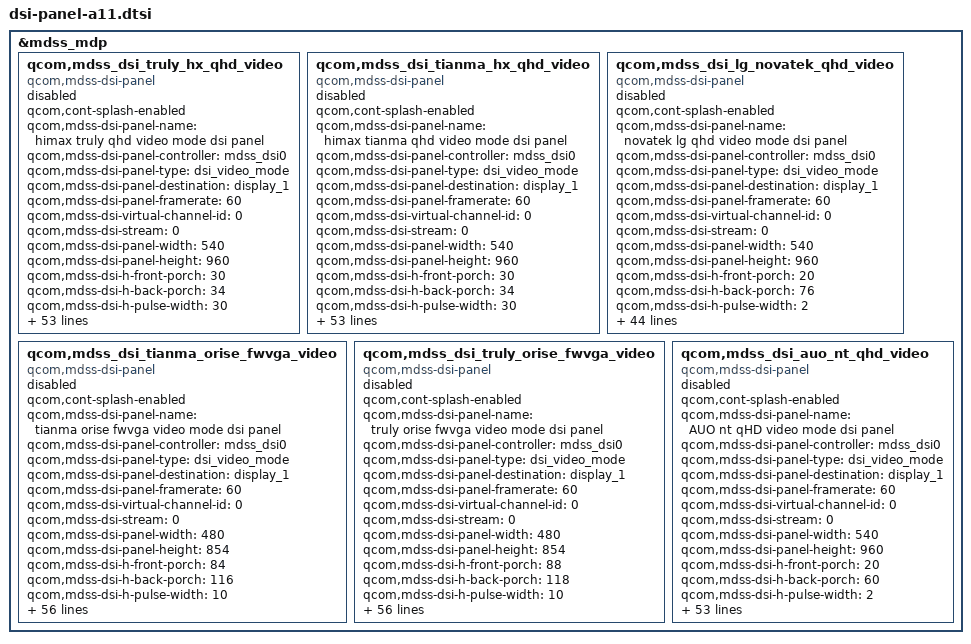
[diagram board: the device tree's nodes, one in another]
&mdss_mdp {
	qcom,mdss_dsi_truly_hx_qhd_video {
		compatible = "qcom,mdss-dsi-panel";
		status = "disabled";
		qcom,cont-splash-enabled;
		qcom,mdss-dsi-panel-name = "himax truly qhd video mode dsi panel";
		qcom,mdss-dsi-panel-controller = <&mdss_dsi0>;
		qcom,mdss-dsi-panel-type = "dsi_video_mode";

		qcom,mdss-dsi-panel-destination = "display_1";
		qcom,mdss-dsi-panel-framerate = <60>;
		qcom,mdss-dsi-virtual-channel-id = <0>;
		qcom,mdss-dsi-stream = <0>;
		qcom,mdss-dsi-panel-width = <540>;
		qcom,mdss-dsi-panel-height = <960>;
		qcom,mdss-dsi-h-front-porch = <30>;
		qcom,mdss-dsi-h-back-porch = <34>;
		qcom,mdss-dsi-h-pulse-width = <30>;
		qcom,mdss-dsi-h-sync-skew = <0>;
		qcom,mdss-dsi-v-back-porch = <13>;
		qcom,mdss-dsi-v-front-porch = <8>;
		qcom,mdss-dsi-v-pulse-width = <5>;
		qcom,mdss-dsi-h-left-border = <0>;
		qcom,mdss-dsi-h-right-border = <0>;
		qcom,mdss-dsi-v-top-border = <0>;
		qcom,mdss-dsi-v-bottom-border = <0>;
		qcom,mdss-dsi-bpp = <24>;
		qcom,mdss-dsi-color-order = <0>;
		qcom,mdss-dsi-underflow-color = <0xff>;
		qcom,mdss-dsi-border-color = <0>;
		/*
			. init command patched
			. 0xE0, 0xC1 command patched
		*/
		qcom,mdss-dsi-on-command = [
			39 01 00 00 01 00 04 B9 FF 83 89
			39 01 00 00 01 00 08 BA 41 93 00 16 A4 00 18
			39 01 00 00 01 00 02 C6 08
			39 01 00 00 01 00 02 CC 02
			39 01 00 00 01 00 03 C0 43 15

			39 01 00 00 01 00 14 B1 00 00 04 E3 9E 10 11 6F EF 28 30 23 23 42 00 58 F2 20 00
			39 01 00 00 01 00 04 DE 05 58 10
			39 01 00 00 0A 00 08 B2 00 00 78 08 03 00 80

			39 01 00 00 0A 00 18 B4 80 08 00 32 10 00 00 00 00 00 00 00 37 0A 40 04 37 0A 40 14 FF FF 0A

			39 01 00 00 0A 00 31 D5 00 00 4C 00 01 00 00 00 60 00 99 88 99 88 88 32 88 10 88 76 88 54 10 32 88 88 88 88 88 88 99 88 99 88 45 88 67 88 01 88 23 23 01 88 88 88 88 88

			39 01 00 00 05 00 23 E0 00 05 09 2A 2E 3F 15 37 05 0B 10 12 14 12 13 11 19 00 04 08 2A 2F 3F 16 38 06 0C 0E 11 13 12 13 10 17
			39 01 00 00 01 00 80 C1 01 00 0B 14 1A 24 2B 33 3B 44 4B 54 5C 64 6D 75 7D 85 8D 95 9E A7 B0 B8 C0 C8 CD D5 DD E4 EB F4 F8 FF 12 3B 72 92 5D 00 73 B3 C0 00 08 11 18 20 27 2F 37 3E 46 4D 55 5C 64 6C 74 7B 82 8A 92 9A A2 AB B4 BB C4 CB D1 DA E3 EB F5 FE 20 68 81 F4 B8 64 E3 51 C0 00 06 0D 15 1D 25 2D 35 3C 44 4B 53 5A 62 6A 71 79 80 87 8E 96 9D A5 AD B4 BC C4 CA D0 D8 E1 E8 F0 00 AC D5 F2 1B 74 C6 A4 00

			39 01 00 00 01 00 02 35 01
			39 01 00 00 01 00 0A C9 0F 00 01 10 00 00 00 01 3A
			/* CABC Command Start */
			39 01 00 00 01 00 02 55 02
			39 01 00 00 01 00 02 5E 11
			39 01 00 00 01 00 0A CA 2D 27 26 25 24 22 21 20 20
			39 01 00 00 01 00 23 CE 00 10 10 10 10 16 16 16 16 16 16 16 16 16 00 00 00 00 00 00 00 00 00 00 00 00 00 00 00 00 00 00 00 00
			/* CABC Command End */
			39 01 00 00 01 00 02 53 2C
			39 01 00 00 01 00 02 E6 00
			39 01 00 00 01 00 02 E3 01
			05 01 00 00 C8 00 02 11 00
			];
		qcom,mdss-dsi-off-command = [05 01 00 00 01 00 02 28 00
					05 01 00 00 78 00 02 10 00];
		qcom,mdss-dsi-on-command-state = "dsi_lp_mode";
		qcom,mdss-dsi-off-command-state = "dsi_hs_mode";
		qcom,mdss-dsi-h-sync-pulse = <1>;
		qcom,mdss-dsi-traffic-mode = <1>;
		qcom,mdss-dsi-bllp-eof-power-mode;
		qcom,mdss-dsi-lane-map = <0>;
		qcom,mdss-dsi-bllp-power-mode;
		qcom,mdss-dsi-lane-0-state;
		qcom,mdss-dsi-lane-1-state;
		qcom,mdss-dsi-panel-timings =  [87 20 12 00 40 44 16 22 17 03 04 00];
		qcom,mdss-dsi-t-clk-post = <0x1f>;
		qcom,mdss-dsi-t-clk-pre = <0x39>;
		qcom,mdss-dsi-bl-min-level = <1>;
		qcom,mdss-dsi-bl-max-level = <255>;
		qcom,mdss-dsi-dma-trigger = <0x04>;
		qcom,mdss-dsi-mdp-trigger = <0x0>;
		qcom,mdss-dsi-bl-pmic-control-type = "bl_ctrl_dcs";

		qcom,display-on-cmds = [05 01 00 00 64 00 02 29 00];
		qcom,mdss-dsi-default-command-state = "dsi_hs_mode";
		qcom,mdss-pan-physical-width-dimension = <58>;
		qcom,mdss-pan-physical-height-dimension = <103>;
		qcom,mdss-shrink-pwm = <16 113 255>;
		qcom,mdss-dsi-lp11-init;
		htc,mdss-camera-blk = <213>;
		htc,panel-id=<0>;
		htc,cabc-off-cmds = [
			39 01 00 00 01 00 02 55 00
			];
		htc,cabc-ui-cmds = [
			39 01 00 00 05 00 02 55 02
			39 01 00 00 01 00 02 5E 11
			39 01 00 00 01 00 0A CA 2D 27 26 25 24 22 21 20 20
			39 01 00 00 01 00 23 CE 00 10 10 10 10 16 16 16 16 16 16 16 16 16 00 00 00 00 00 00 00 00 00 00 00 00 00 00 00 00 00 00 00 00
			];
		htc,cabc-video-cmds = [
			39 01 00 00 05 00 02 55 03
			39 01 00 00 01 00 02 5E 11
			39 01 00 00 01 00 0A CA 40 30 2F 2E 2D 26 22 20 20
			39 01 00 00 01 00 23 CE 00 18 1A 1A 20 20 20 20 28 28 28 28 28 28 28 28 30 30 30 30 30 30 30 30 30 30 30 30 30 30 30 30 30 00
			];
		htc,dimming-on-cmds = [39 01 00 00 00 00 02 53 2C];
	};
	qcom,mdss_dsi_tianma_hx_qhd_video {
		compatible = "qcom,mdss-dsi-panel";
		status = "disabled";
		qcom,cont-splash-enabled;
		qcom,mdss-dsi-panel-name = "himax tianma qhd video mode dsi panel";
		qcom,mdss-dsi-panel-controller = <&mdss_dsi0>;
		qcom,mdss-dsi-panel-type = "dsi_video_mode";

		qcom,mdss-dsi-panel-destination = "display_1";
		qcom,mdss-dsi-panel-framerate = <60>;
		qcom,mdss-dsi-virtual-channel-id = <0>;
		qcom,mdss-dsi-stream = <0>;
		qcom,mdss-dsi-panel-width = <540>;
		qcom,mdss-dsi-panel-height = <960>;
		qcom,mdss-dsi-h-front-porch = <30>;
		qcom,mdss-dsi-h-back-porch = <34>;
		qcom,mdss-dsi-h-pulse-width = <30>;
		qcom,mdss-dsi-h-sync-skew = <0>;
		qcom,mdss-dsi-v-back-porch = <13>;
		qcom,mdss-dsi-v-front-porch = <8>;
		qcom,mdss-dsi-v-pulse-width = <5>;
		qcom,mdss-dsi-h-left-border = <0>;
		qcom,mdss-dsi-h-right-border = <0>;
		qcom,mdss-dsi-v-top-border = <0>;
		qcom,mdss-dsi-v-bottom-border = <0>;
		qcom,mdss-dsi-bpp = <24>;
		qcom,mdss-dsi-color-order = <0>;
		qcom,mdss-dsi-underflow-color = <0xff>;
		qcom,mdss-dsi-border-color = <0>;
		/*
			. init command patched
		*/
		qcom,mdss-dsi-on-command = [
			/* exit sleep */
			05 01 00 00 78 00 02 11 00

			39 01 00 00 01 00 04 B9 FF 83 89
			39 01 00 00 01 00 08 BA 41 93 00 16 A4 00 18
			39 01 00 00 01 00 02 C6 08
			39 01 00 00 01 00 02 CC 02
			39 01 00 00 01 00 14 B1 00 00 07 DE 41 10 11 93 EE 26 2E 3F 3F 42 01 32 F4 20 80
			39 01 00 00 01 00 04 DE 05 58 10
			39 01 00 00 0A 00 08 B2 00 00 78 0E 03 3F 80

			39 01 00 00 0A 00 18 B4 80 08 00 32 10 07 32 10 03 32 10 07 27 01 5A 0B 37 05 4C 14 FF 58 0A

			39 01 00 00 0A 00 31 D5 00 00 00 00 01 00 00 01 60 00 99 88 88 88 88 23 88 01 88 67 88 45 01 23 23 45 88 88 88 88 99 88 88 88 54 88 76 88 10 88 32 32 10 88 88 88 88 88

			39 01 00 00 0A 00 23 E0 00 21 24 3A 3F 3F 31 4E 07 0C 0F 12 14 11 13 10 17 00 21 23 38 3F 3F 31 4D 08 0D 0E 12 14 11 13 10 19

			39 01 00 00 05 00 80 C1 01 00 06 13 18 20 2A 32 39 42 49 51 59 5F 68 71 7C 83 8B 94 9C A4 AE B6 BE C6 CA D3 DB E3 EB F3 FD FF 03 AA 62 C9 B5 C5 BA 0C C0 00 08 12 18 1F 29 31 38 40 47 4E 55 5C 62 6A 73 7B 83 8A 91 99 A1 A8 B0 B8 BF C9 CE D5 E0 E8 F0 FA 00 1A 12 3D C6 89 78 00 C0 00 08 0E 15 1D 28 31 38 40 47 4E 56 5C 63 6C 75 7D 84 8C 93 9C A3 AB B3 BB C3 CB D1 D8 E2 E9 F1 F8 03 A6 68 F4 77 3B 99 80 00
			39 01 00 00 01 00 02 35 01
			39 01 00 00 01 00 0A C9 0F 00 01 10 00 00 00 01 3A

			/* CABC Command Start */
			39 01 00 00 05 00 02 55 02
			39 01 00 00 01 00 02 5E 11
			39 01 00 00 01 00 0A CA 2D 27 26 25 24 22 21 21 20
			39 01 00 00 01 00 23 CE 00 00 00 00 10 10 16 16 16 16 16 16 16 16 00 00 00 00 00 00 00 00 00 00 00 00 00 00 00 00 00 00 00 00
			/* CABC Command End */

			/* CE Command Start */
			39 01 00 00 01 00 02 E6 00
			39 01 00 00 01 00 02 E3 01
			/* CE Command End */

			39 01 00 00 01 00 02 53 2C
			];
		qcom,mdss-dsi-off-command = [05 01 00 00 01 00 02 28 00
					05 01 00 00 78 00 02 10 00];
		qcom,mdss-dsi-on-command-state = "dsi_lp_mode";
		qcom,mdss-dsi-off-command-state = "dsi_hs_mode";
		qcom,mdss-dsi-h-sync-pulse = <1>;
		qcom,mdss-dsi-traffic-mode = <1>;
		qcom,mdss-dsi-bllp-eof-power-mode;
		qcom,mdss-dsi-lane-map = <0>;
		qcom,mdss-dsi-bllp-power-mode;
		qcom,mdss-dsi-lane-0-state;
		qcom,mdss-dsi-lane-1-state;
		qcom,mdss-dsi-panel-timings =  [87 20 12 00 40 44 16 22 17 03 04 00];
		qcom,mdss-dsi-t-clk-post = <0x1f>;
		qcom,mdss-dsi-t-clk-pre = <0x39>;
		qcom,mdss-dsi-bl-min-level = <1>;
		qcom,mdss-dsi-bl-max-level = <255>;
		qcom,mdss-dsi-dma-trigger = <0x04>;
		qcom,mdss-dsi-mdp-trigger = <0x0>;
		qcom,mdss-dsi-bl-pmic-control-type = "bl_ctrl_dcs";

		qcom,display-on-cmds = [05 01 00 00 0a 00 02 29 00];
		qcom,mdss-dsi-default-command-state = "dsi_hs_mode";
		qcom,mdss-pan-physical-width-dimension = <58>;
		qcom,mdss-pan-physical-height-dimension = <103>;
		qcom,mdss-shrink-pwm = <16 113 255>;
		qcom,mdss-dsi-lp11-init;
		htc,mdss-camera-blk = <213>;
		htc,cabc-off-cmds = [
			39 01 00 00 01 00 02 55 00
			];
		htc,cabc-ui-cmds = [
			39 01 00 00 05 00 02 55 02
			39 01 00 00 01 00 02 5E 11
			39 01 00 00 01 00 0A CA 2D 27 26 25 24 22 21 21 20
			39 01 00 00 01 00 23 CE 00 00 00 00 10 10 16 16 16 16 16 16 16 16 00 00 00 00 00 00 00 00 00 00 00 00 00 00 00 00 00 00 00 00
			];
		htc,cabc-video-cmds = [
			39 01 00 00 05 00 02 55 03
			39 01 00 00 01 00 02 5E 11
			39 01 00 00 01 00 0A CA 40 30 2F 2E 2D 26 23 21 20
			39 01 00 00 01 00 23 CE 00 00 00 10 10 10 10 20 20 20 20 20 20 20 30 30 30 30 30 30 30 30 30 30 30 30 30 30 30 30 30 30 30 00
			];
		htc,dimming-on-cmds = [39 01 00 00 00 00 02 53 2C];
		htc,panel-id=<0>;
	};

	qcom,mdss_dsi_lg_novatek_qhd_video{
		compatible = "qcom,mdss-dsi-panel";
		status = "disabled";
		qcom,cont-splash-enabled;
		qcom,mdss-dsi-panel-name = "novatek lg qhd video mode dsi panel";
		qcom,mdss-dsi-panel-controller = <&mdss_dsi0>;
		qcom,mdss-dsi-panel-type = "dsi_video_mode";

		qcom,mdss-dsi-panel-destination = "display_1";
		qcom,mdss-dsi-panel-framerate = <60>;
		qcom,mdss-dsi-virtual-channel-id = <0>;
		qcom,mdss-dsi-stream = <0>;
		qcom,mdss-dsi-panel-width = <540>;
		qcom,mdss-dsi-panel-height = <960>;
		qcom,mdss-dsi-h-front-porch = <20>;
		qcom,mdss-dsi-h-back-porch = <76>;
		qcom,mdss-dsi-h-pulse-width = <2>;
		qcom,mdss-dsi-h-sync-skew = <0>;
		qcom,mdss-dsi-v-back-porch = <20>;
		qcom,mdss-dsi-v-front-porch = <20>;
		qcom,mdss-dsi-v-pulse-width = <2>;
		qcom,mdss-dsi-h-left-border = <0>;
		qcom,mdss-dsi-h-right-border = <0>;
		qcom,mdss-dsi-v-top-border = <0>;
		qcom,mdss-dsi-v-bottom-border = <0>;
		qcom,mdss-dsi-bpp = <24>;
		qcom,mdss-dsi-color-order = <0>;
		qcom,mdss-dsi-underflow-color = <0xff>;
		qcom,mdss-dsi-border-color = <0>;
		qcom,mdss-dsi-on-command = [
			39 01 00 00 01 00 06 F0 55 AA 52 08 01
			15 01 00 00 01 00 02 B6 34
			15 01 00 00 01 00 02 B7 44
			15 01 00 00 01 00 02 B8 13
			15 01 00 00 01 00 02 B9 23
			39 01 00 00 01 00 04 BC 00 B8 00
			39 01 00 00 01 00 04 BD 00 B4 00
			15 01 00 00 01 00 02 BE 6A
			39 01 00 00 01 00 03 C0 04 00
			15 01 00 00 01 00 02 CF 04
			39 01 00 00 01 00 11 D1 00 75 00 B4 00 D9 00 F8 01 06 01 1F 01 31 01 52
			39 01 00 00 01 00 11 D2 01 76 01 AC 01 D1 02 0C 02 3D 02 41 02 6C 02 9E
			39 01 00 00 01 00 11 D3 02 BA 02 EC 03 12 03 34 03 4C 03 66 03 74 03 86
			39 01 00 00 01 00 05 D4 03 9B 03 C7
			15 01 00 00 78 00 02 11 00
			39 01 00 00 01 00 06 F0 55 AA 52 08 00
			39 01 00 00 01 00 04 B1 68 00 01
			15 01 00 00 01 00 02 B4 78
			39 01 00 00 01 00 05 B8 01 02 02 02
			39 01 00 00 01 00 04 BC 00 00 00
			39 01 00 00 01 00 07 C9 63 06 0D 1A 17 00
			15 01 00 00 01 00 02 53 2C
			15 01 00 00 01 00 02 35 00
			39 01 00 00 01 00 03 E0 00 02
			39 01 00 00 01 00 05 FF AA 55 25 01
			15 01 00 00 01 00 02 6F 0A
			15 01 00 00 01 00 02 FA 03
			15 01 00 00 01 00 02 13 00
			15 01 00 00 01 00 02 51 FF];
		qcom,mdss-dsi-off-command = [05 01 00 00 01 00 02 28 00
					05 01 00 00 78 00 02 10 00];
		qcom,mdss-dsi-on-command-state = "dsi_lp_mode";
		qcom,mdss-dsi-off-command-state = "dsi_hs_mode";
		qcom,mdss-dsi-h-sync-pulse = <1>;
		qcom,mdss-dsi-traffic-mode = <1>;
		qcom,mdss-dsi-bllp-eof-power-mode;
		qcom,mdss-dsi-lane-map = <0>;
		qcom,mdss-dsi-bllp-power-mode;
		qcom,mdss-dsi-lane-0-state;
		qcom,mdss-dsi-lane-1-state;
		qcom,mdss-dsi-panel-timings =  [37 27 20 01 3c 39 21 29 32 03 04 00]; //?
		qcom,mdss-dsi-t-clk-post = <0x1f>;
		qcom,mdss-dsi-t-clk-pre = <0x39>;
		qcom,mdss-dsi-bl-min-level = <1>;
		qcom,mdss-dsi-bl-max-level = <255>;
		qcom,mdss-dsi-dma-trigger = <0x04>;
		qcom,mdss-dsi-mdp-trigger = <0x0>;
		qcom,mdss-dsi-bl-pmic-control-type = "bl_ctrl_dcs";

		qcom,display-on-cmds = [05 01 00 00 01 00 02 29 00];
		qcom,mdss-dsi-default-command-state = "dsi_hs_mode";
		qcom,mdss-pan-physical-width-dimension = <61>;
		qcom,mdss-pan-physical-height-dimension = <106>;
		qcom,mdss-shrink-pwm = <16 113 255>;
		htc,mdss-camera-blk = <213>;
		htc,panel-id=<0>;
	};
	qcom,mdss_dsi_tianma_orise_fwvga_video{
		compatible = "qcom,mdss-dsi-panel";
		status = "disabled";
		qcom,cont-splash-enabled;
		qcom,mdss-dsi-panel-name = "tianma orise fwvga video mode dsi panel";
		qcom,mdss-dsi-panel-controller = <&mdss_dsi0>;
		qcom,mdss-dsi-panel-type = "dsi_video_mode";

		qcom,mdss-dsi-panel-destination = "display_1";
		qcom,mdss-dsi-panel-framerate = <60>;
		qcom,mdss-dsi-virtual-channel-id = <0>;
		qcom,mdss-dsi-stream = <0>;
		qcom,mdss-dsi-panel-width = <480>;
		qcom,mdss-dsi-panel-height = <854>;
		qcom,mdss-dsi-h-front-porch = <84>;
		qcom,mdss-dsi-h-back-porch = <116>;
		qcom,mdss-dsi-h-pulse-width = <10>;
		qcom,mdss-dsi-h-sync-skew = <0>;
		qcom,mdss-dsi-v-back-porch = <18>;
		qcom,mdss-dsi-v-front-porch = <18>;
		qcom,mdss-dsi-v-pulse-width = <12>;
		qcom,mdss-dsi-h-left-border = <0>;
		qcom,mdss-dsi-h-right-border = <0>;
		qcom,mdss-dsi-v-top-border = <0>;
		qcom,mdss-dsi-v-bottom-border = <0>;
		qcom,mdss-dsi-bpp = <24>;
		qcom,mdss-dsi-color-order = <0>;
		qcom,mdss-dsi-underflow-color = <0xff>;
		qcom,mdss-dsi-border-color = <0>;
		/*
			. init command patched : add CABC cmds
		*/
		qcom,mdss-dsi-on-command = [
			15 01 00 00 00 00 02 00 00
			39 01 00 00 00 00 04 FF 80 09 01
			15 01 00 00 00 00 02 00 80
			39 01 00 00 00 00 03 FF 80 09
			15 01 00 00 00 00 02 00 03
			15 01 00 00 00 00 02 FF 01
			15 01 00 00 00 00 02 00 B4
			15 01 00 00 00 00 02 C0 50
			15 01 00 00 00 00 02 00 89
			15 01 00 00 00 00 02 C4 08
			15 01 00 00 00 00 02 00 82
			15 01 00 00 00 00 02 C5 A3
			15 01 00 00 00 00 02 00 90
			39 01 00 00 00 00 03 C5 D6 76
			15 01 00 00 00 00 02 00 00
			39 01 00 00 00 00 03 D8 6F 6F
			15 01 00 00 00 00 02 00 00
			15 01 00 00 00 00 02 00 81
			15 01 00 00 00 00 02 C1 66
			15 01 00 00 00 00 02 00 A1
			15 01 00 00 00 00 02 C1 EA
			15 01 00 00 00 00 02 00 81
			15 01 00 00 00 00 02 C4 83
			15 01 00 00 00 00 02 00 92
			15 01 00 00 00 00 02 C5 01
			15 01 00 00 00 00 02 00 B1
			15 01 00 00 00 00 02 C5 A9
			15 01 00 00 00 00 02 00 A6
			15 01 00 00 00 00 02 C1 01
			15 01 00 00 00 00 02 00 C0
			15 01 00 00 00 00 02 C5 00
			15 01 00 00 00 00 02 00 8B
			15 01 00 00 00 00 02 B0 40
			15 01 00 00 00 00 02 00 B2
			39 01 00 00 00 00 05 F5 15 00 15 00
			15 01 00 00 00 00 02 00 93
			15 01 00 00 00 00 02 C5 03
			15 01 00 00 00 00 02 00 90
			15 01 00 00 00 00 02 B3 02
			15 01 00 00 00 00 02 00 92
			15 01 00 00 00 00 02 B3 45
			15 01 00 00 00 00 02 00 80
			39 01 00 00 00 00 0a C0 00 58 00 15 15 00 58 15 15
			15 01 00 00 00 00 02 00 90
			39 01 00 00 00 00 07 C0 00 44 00 00 00 03
			15 01 00 00 00 00 02 00 A6
			39 01 00 00 00 00 04 C1 01 00 00
			15 01 00 00 00 00 02 00 80
			39 01 00 00 00 00 0d CE 8B 03 00 8A 03 00 89 03 00 88 03 00
			15 01 00 00 00 00 02 00 90
			39 01 00 00 00 00 0d CE 38 0A 00 38 0B 00 38 0C 00 38 0D 00
			15 01 00 00 00 00 02 00 A0
			39 01 00 00 00 00 0f CE 38 07 03 54 00 25 00 38 06 03 55 00 25 00
			15 01 00 00 00 00 02 00 B0
			39 01 00 00 00 00 0f CE 38 05 03 56 00 25 00 38 04 03 57 00 25 00
			15 01 00 00 00 00 02 00 C0
			39 01 00 00 00 00 0f CE 38 03 03 58 00 25 00 38 02 03 59 00 25 00
			15 01 00 00 00 00 02 00 D0
			39 01 00 00 00 00 0f CE 38 09 03 5A 00 25 00 38 08 03 5B 00 25 00
			15 01 00 00 00 00 02 00 C0
			39 01 00 00 00 00 10 CB 04 04 00 00 04 04 04 04 04 04 00 00 00 00 00
			15 01 00 00 00 00 02 00 D0
			39 01 00 00 00 00 10 CB 00 00 00 00 00 04 04 00 00 04 04 04 04 04 04
			15 01 00 00 00 00 02 00 E0
			39 01 00 00 00 00 0b CB 00 00 00 00 00 00 00 00 00 00
			15 01 00 00 00 00 02 00 80
			39 01 00 00 00 00 0b CC 26 25 00 00 0C 0A 10 0E 02 04
			15 01 00 00 00 00 02 00 90
			39 01 00 00 00 00 10 CC 00 00 00 00 00 00 00 00 00 00 26 25 00 00 0B
			15 01 00 00 00 00 02 00 A0
			39 01 00 00 00 00 10 CC 09 0F 0D 01 03 00 00 00 00 00 00 00 00 00 00
			15 01 00 00 00 00 02 00 B0
			39 01 00 00 00 00 0b CC 25 26 00 00 0B 0D 0F 09 06 08
			15 01 00 00 00 00 02 00 C0
			39 01 00 00 00 00 10 CC 00 00 00 00 00 00 00 00 00 00 25 26 00 00 0C
			15 01 00 00 00 00 02 00 D0
			39 01 00 00 00 00 10 CC 0E 10 0A 05 07 00 00 00 00 00 00 00 00 00 00
			15 01 00 00 00 00 02 00 00
			39 01 00 00 00 00 11 E1 00 03 09 0F 09 1C 0E 0E 01 05 03 08 0F 25 21 00
			15 01 00 00 00 00 02 00 00
			39 01 00 00 00 00 11 E2 00 03 09 0F 09 1C 0E 0D 00 05 03 07 0F 25 21 00
			15 01 00 00 00 00 02 00 00
			39 01 00 00 00 00 22 EC 50 55 55 45 45 45 45 45 45 45 45 45 45 45 45 44 44 44 44 44 44 44 44 44 33 33 33 33 33 33 33 33 44
			15 01 00 00 00 00 02 00 00
			39 01 00 00 00 00 22 ED 40 33 44 44 44 44 44 44 46 43 43 44 44 44 44 44 44 44 44 44 44 44 44 44 44 44 44 44 44 44 44 44 44
			15 01 00 00 00 00 02 00 00
			39 01 00 00 00 00 22 EE 30 34 24 24 24 24 24 24 24 24 24 24 22 24 24 24 24 34 34 34 34 34 34 34 34 34 34 34 55 55 55 55 44
			15 01 00 00 00 00 02 00 80
			39 01 00 00 00 00 1D CA 80 6e 79 84 8f 9a a5 b0 bb c6 d1 dc e7 f2 f2 f2 af ff af ff 63 ff 05 03 05 03 05 03
			15 01 00 00 00 00 02 00 00
			15 01 00 00 00 00 02 c7 10
			39 01 00 00 00 00 13 C8 d0 f9 db bb ca bb df ee 9d ba 88 67 45 23 22 12 11 11
			15 01 00 00 00 00 02 00 00
			15 01 00 00 00 00 02 c7 11
			39 01 00 00 00 00 13 C8 c0 e9 c9 ba aa cb ce ec 9d b9 88 78 56 23 22 22 22 22
			15 01 00 00 00 00 02 00 00
			15 01 00 00 00 00 02 c7 12
			39 01 00 00 00 00 13 C8 c0 e9 b9 aa 9a bb cc eb 9d a9 88 78 56 34 33 33 33 23
			15 01 00 00 00 00 02 00 00
			15 01 00 00 00 00 02 c7 13
			39 01 00 00 00 00 13 C8 c0 d8 ba b9 69 ca ba cd 9d aa 88 88 67 45 33 33 33 33
			15 01 00 00 00 00 02 00 00
			15 01 00 00 00 00 02 c7 14
			39 01 00 00 00 00 13 C8 b0 b9 c9 a9 9a b8 99 bd 9d a9 88 88 67 45 44 44 44 44
			15 01 00 00 00 00 02 00 00
			15 01 00 00 00 00 02 c7 15
			39 01 00 00 00 00 13 C8 b0 b8 b9 9a 8a c9 6a c9 8c aa 88 88 78 56 45 44 44 44
			15 01 00 00 00 00 02 00 00
			15 01 00 00 00 00 02 c7 16
			39 01 00 00 00 00 13 C8 a0 a9 a9 9a 8a a9 8a ab 89 aa 88 88 78 56 55 55 55 44
			15 01 00 00 00 00 02 00 00
			15 01 00 00 00 00 02 c7 17
			39 01 00 00 00 00 13 C8 a0 a8 a9 89 8b 99 8a c9 9b 87 88 88 88 67 56 55 55 55
			15 01 00 00 00 00 02 00 00
			15 01 00 00 00 00 02 c7 18
			39 01 00 00 00 00 13 C8 a0 98 99 99 99 a8 8a b8 7b aa 67 86 88 67 66 66 66 55
			15 01 00 00 00 00 02 00 00
			15 01 00 00 00 00 02 c7 19
			39 01 00 00 00 00 13 C8 a0 98 98 89 8a 88 7c 99 8b a8 88 68 86 78 67 66 66 66
			15 01 00 00 00 00 02 00 00
			15 01 00 00 00 00 02 c7 1A
			39 01 00 00 00 00 13 C8 90 89 89 89 89 98 89 98 8b a7 88 88 88 67 77 77 77 66
			15 01 00 00 00 00 02 00 00
			15 01 00 00 00 00 02 c7 1B
			39 01 00 00 00 00 13 C8 90 98 88 89 89 88 89 88 8a a8 88 88 88 88 77 77 77 77
			15 01 00 00 00 00 02 00 00
			15 01 00 00 00 00 02 c7 1C
			39 01 00 00 00 00 13 C8 90 88 88 89 88 88 89 88 89 98 88 88 88 88 88 68 75 77
			15 01 00 00 00 00 02 00 00
			15 01 00 00 00 00 02 c7 1D
			39 01 00 00 00 00 13 C8 80 88 88 88 88 88 88 88 88 88 88 88 88 88 88 88 88 88
			15 01 00 00 00 00 02 00 00
			15 01 00 00 00 00 02 C7 00
			15 01 00 00 00 00 02 00 C7
			15 01 00 00 00 00 02 CF 80
			15 01 00 00 00 00 02 00 C9
			15 01 00 00 00 00 02 CF 05
			15 01 00 00 00 00 02 00 92
			39 01 00 00 00 00 03 C0 00 02
			15 01 00 00 00 00 02 00 94
			39 01 00 00 00 00 03 C0 00 05
			15 01 00 00 00 00 02 00 a0
			15 01 00 00 00 00 02 c1 ea
			15 01 00 00 00 00 02 00 c6
			15 01 00 00 00 00 02 b0 03
			15 01 00 00 00 00 02 00 b6
			15 01 00 00 00 00 02 f5 06
			15 01 00 00 00 00 02 00 b1
			15 01 00 00 00 00 02 b0 80
			15 01 00 00 00 00 02 00 92
			39 01 00 00 00 00 08 f5 0e 14 0e 14 00 14 00
			15 01 00 00 00 00 02 00 80
			39 01 00 00 00 00 03 ff ff ff
			15 01 00 00 00 00 02 00 00
			39 01 00 00 00 00 04 ff ff ff ff
			15 01 00 00 00 00 02 00 00
			15 01 00 00 00 00 02 53 2C
			15 01 00 00 00 00 02 00 00
			15 01 00 00 00 00 02 55 02
			15 01 00 00 00 00 02 00 00
			39 01 00 00 00 00 04 ff 80 09 01
			15 01 00 00 00 00 02 00 80
			39 01 00 00 00 00 03 ff 80 09
			15 01 00 00 00 00 02 00 80
			15 01 00 00 00 00 02 d6 48
			15 01 00 00 00 00 02 00 80
			39 01 00 00 00 00 03 ff ff ff
			15 01 00 00 00 00 02 00 00
			39 01 00 00 00 00 04 ff ff ff ff
			05 01 00 00 78 00 02 11 00];
		qcom,mdss-dsi-off-command = [05 01 00 00 01 00 02 28 00
					05 01 00 00 82 00 02 10 00];
		qcom,mdss-dsi-on-command-state = "dsi_lp_mode";
		qcom,mdss-dsi-off-command-state = "dsi_hs_mode";
		qcom,mdss-dsi-h-sync-pulse = <1>;
		qcom,mdss-dsi-traffic-mode = <1>;
		qcom,mdss-dsi-bllp-eof-power-mode;
		qcom,mdss-dsi-lane-map = <0>;
		qcom,mdss-dsi-bllp-power-mode;
		qcom,mdss-dsi-lane-0-state;
		qcom,mdss-dsi-lane-1-state;
		qcom,mdss-dsi-panel-timings =  [c9 23 1b 00 36 31 20 25 2c 03 04 00];
		qcom,mdss-dsi-t-clk-post = <0x1f>;
		qcom,mdss-dsi-t-clk-pre = <0x39>;
		qcom,mdss-dsi-bl-min-level = <1>;
		qcom,mdss-dsi-bl-max-level = <255>;
		qcom,mdss-dsi-dma-trigger = <0x04>;
		qcom,mdss-dsi-mdp-trigger = <0x0>;
		qcom,mdss-dsi-bl-pmic-control-type = "bl_ctrl_dcs";

		qcom,display-on-cmds = [05 01 00 00 32 00 02 29 00];
		qcom,mdss-dsi-default-command-state = "dsi_hs_mode";
		qcom,mdss-pan-physical-width-dimension = <58>;
		qcom,mdss-pan-physical-height-dimension = <103>;
		qcom,mdss-shrink-pwm = <8 113 255>;
		qcom,mdss-shrink-pwm-power-hack = <16 73 255>;
		qcom,mdss-dsi-panel-framerate-power-hack = <56>;
		qcom,cont-splash-power-hack = <0>;
		qcom,mdss-dsi-lp11-init;
		htc,mdss-camera-blk = <213>;
		htc,panel-id=<0>;
		htc,cabc-off-cmds = [39 01 00 00 00 00 02 55 00];
		htc,cabc-ui-cmds = [39 01 00 00 00 00 02 55 02];
		htc,cabc-video-cmds = [39 01 00 00 00 00 02 55 03];
		htc,dimming-on-cmds = [39 01 00 00 00 00 02 53 2C];
		htc,mdss-pp-hue = <0x0>;
	};

	qcom,mdss_dsi_truly_orise_fwvga_video{
		compatible = "qcom,mdss-dsi-panel";
		status = "disabled";
		qcom,cont-splash-enabled;
		qcom,mdss-dsi-panel-name = "truly orise fwvga video mode dsi panel";
		qcom,mdss-dsi-panel-controller = <&mdss_dsi0>;
		qcom,mdss-dsi-panel-type = "dsi_video_mode";

		qcom,mdss-dsi-panel-destination = "display_1";
		qcom,mdss-dsi-panel-framerate = <60>;
		qcom,mdss-dsi-virtual-channel-id = <0>;
		qcom,mdss-dsi-stream = <0>;
		qcom,mdss-dsi-panel-width = <480>;
		qcom,mdss-dsi-panel-height = <854>;
		qcom,mdss-dsi-h-front-porch = <88>;
		qcom,mdss-dsi-h-back-porch = <118>;
		qcom,mdss-dsi-h-pulse-width = <10>;
		qcom,mdss-dsi-h-sync-skew = <0>;
		qcom,mdss-dsi-v-back-porch = <16>;
		qcom,mdss-dsi-v-front-porch = <16>;
		qcom,mdss-dsi-v-pulse-width = <12>;
		qcom,mdss-dsi-h-left-border = <0>;
		qcom,mdss-dsi-h-right-border = <0>;
		qcom,mdss-dsi-v-top-border = <0>;
		qcom,mdss-dsi-v-bottom-border = <0>;
		qcom,mdss-dsi-bpp = <24>;
		qcom,mdss-dsi-color-order = <0>;
		qcom,mdss-dsi-underflow-color = <0xff>;
		qcom,mdss-dsi-border-color = <0>;
		/*
			. init command patched : CABC
			. remove 'add start' block caused display abnormal
		*/
		qcom,mdss-dsi-on-command = [
			//new code modify by ors dim  140607
			39 01 00 00 00 00 02 00 00
			29 01 00 00 00 00 04 ff 80 09 01

			39 01 00 00 00 00 02 00 80
			29 01 00 00 00 00 03 ff 80 09

			//OTM8018B initial code ...
			39 01 00 00 00 00 02 00 D2
			29 01 00 00 00 00 02 B0 01  //MIPI Setting

			39 01 00 00 00 00 02 00 80
			29 01 00 00 00 00 0D f5 01 14 02 14 10 14 02 14 0e 14 0f 20

			39 01 00 00 00 00 02 00 90
			29 01 00 00 00 00 0B f5 02 14 08 14 06 14 0d 14 0b 14

			39 01 00 00 00 00 02 00 a0
			29 01 00 00 00 00 09 f5 10 14 01 14 14 14 14 14

			39 01 00 00 00 00 02 00 b0
			29 01 00 00 00 00 0D f5 14 14 12 14 13 14 11 14 13 14 00 00

			39 01 00 00 00 00 02 00 80
			29 01 00 00 00 00 02 c4 30

			39 01 00 00 00 00 02 00 8a
			29 01 00 00 00 00 02 c4 40

			39 01 00 00 00 00 02 00 03
			29 01 00 00 00 00 02 ff 01

			39 01 00 00 00 00 02 00 00
			29 01 00 00 00 00 03 d8 6F 6F //GVDD & NGVDD = 4.5V

			39 01 00 00 00 00 02 00 82
			29 01 00 00 00 00 02 c5 a3

			39 01 00 00 00 00 02 00 81
			29 01 00 00 00 00 02 c1 77

			39 01 00 00 00 00 02 00 a1
			29 01 00 00 00 00 02 c1 08

			39 01 00 00 00 00 02 00 90
			29 01 00 00 00 00 04 c5 96 99 01

			39 01 00 00 00 00 02 00 b1
			29 01 00 00 00 00 02 c5 a9

			39 01 00 00 00 00 02 00 90
			29 01 00 00 00 00 02 b3 02

			39 01 00 00 00 00 02 00 92
			29 01 00 00 00 00 02 b3 45

			39 01 00 00 00 00 02 00 a1
			29 01 00 00 00 00 02 b3 10

			39 01 00 00 00 00 02 00 a6
			29 01 00 00 00 00 03 b3 20 00

			39 01 00 00 00 00 02 00 a0
			29 01 00 00 00 00 02 c1 fa

			39 01 00 00 00 00 02 00 b4
			29 01 00 00 00 00 03 c0 50 48

			39 01 00 00 00 00 02 00 00
			39 01 00 00 00 00 02 36 00

			39 01 00 00 00 00 02 00 80
			29 01 00 00 00 00 06 c0 00 58 00 14 16

			39 01 00 00 00 00 02 00 90
			29 01 00 00 00 00 07 c0 00 44 00 00 00 03

			39 01 00 00 00 00 02 00 a6
			29 01 00 00 00 00 04 c1 00 00 00

			39 01 00 00 00 00 02 00 80
			29 01 00 00 00 00 07 ce 87 03 00 86 03 00

			39 01 00 00 00 00 02 00 90
			29 01 00 00 00 00 07 ce 33 55 00 33 56 00

			39 01 00 00 00 00 02 00 a0
			29 01 00 00 00 00 0F ce 38 03 03 58 00 00 00 38 02 03 59 00 00 00

			39 01 00 00 00 00 02 00 b0
			29 01 00 00 00 00 0F ce 38 01 03 5a 00 00 00 38 00 03 5b 00 00 00

			39 01 00 00 00 00 02 00 c0
			29 01 00 00 00 00 0F ce 30 00 03 5c 00 00 00 30 01 03 5d 00 00 00

			39 01 00 00 00 00 02 00 d0
			29 01 00 00 00 00 0F ce 38 05 03 5e 00 00 00 38 04 03 5f 00 00 00

			39 01 00 00 00 00 02 00 c0
			29 01 00 00 00 00 0B cf 00 00 00 00 00 00 01 80 00 09

			39 01 00 00 00 00 02 00 c0
			29 01 00 00 00 00 10 cb 00 14 14 14 14 00 00 14 14 14 14 00 00 00 00

			39 01 00 00 00 00 02 00 d0
			29 01 00 00 00 00 10 cb 00 00 00 00 00 00 14 14 14 14 14 00 14 14 14

			39 01 00 00 00 00 02 00 e0
			29 01 00 00 00 00 0B cb 04 00 00 00 00 00 00 00 00 00

			39 01 00 00 00 00 02 00 80
			29 01 00 00 00 00 0B cc 00 26 25 02 06 00 00 0a 0e 0c

			39 01 00 00 00 00 02 00 90
			29 01 00 00 00 00 10 cc 10 00 00 00 00 00 00 00 00 00 00 26 25 01 05

			39 01 00 00 00 00 02 00 a0
			29 01 00 00 00 00 10 cc 00 00 09 0d 0b 0f 00 00 00 00 00 00 00 00 00

			39 01 00 00 00 00 02 00 b0
			29 01 00 00 00 00 0B cc 00 25 26 05 01 00 00 0d 09 0b

			39 01 00 00 00 00 02 00 c0
			29 01 00 00 00 00 10 cc 0f 00 00 00 00 00 00 00 00 00 00 25 26 06 02

			39 01 00 00 00 00 02 00 d0
			29 01 00 00 00 00 10 cc 00 00 0e 0a 0c 10 00 00 00 00 00 00 00 00 00

			39 01 00 00 00 00 02 00 89
			29 01 00 00 00 00 02 c4 00

			39 01 00 00 00 00 02 00 81
			29 01 00 00 00 00 02 c4 80

			39 01 00 00 00 00 02 00 a3
			29 01 00 00 00 00 02 c0 1b

			//Gamma 2.2
			39 01 00 00 00 00 02 00 00
			29 01 00 00 00 00 11 e1 05 08 16 10 09 1d 0c 0c 02 05 03 08 0e 23 1f 05
			39 01 00 00 00 00 02 00 00
			29 01 00 00 00 00 11 e2 05 08 16 10 09 1d 0c 0c 02 05 03 08 0e 23 1f 05
			//Gamma 2.2

			//Digital Gamma
			29 01 00 00 00 00 02 00 00
			29 01 00 00 00 00 22 ec 40 44 44 44 44 44 44 44 44 44 44 44 44 44 44 44 44 44 44 44 44 44 44 44 44 44 44 44 44 44 44 44 44
			//                                        16        32        48        64        80        96       112       128       144       160       176       192       208       224       240      255 
			29 01 00 00 00 00 02 00 00
			29 01 00 00 00 00 22 ed 40 44 44 44 44 44 44 44 44 44 44 44 44 44 44 44 44 44 44 44 44 44 44 44 44 44 44 44 44 44 44 44 44
			29 01 00 00 00 00 02 00 00
			29 01 00 00 00 00 22 ee 40 44 44 44 44 44 44 44 44 44 44 44 44 44 44 44 44 44 44 44 44 44 44 44 44 44 44 44 44 44 44 44 44
			29 01 00 00 00 00 02 00 00
			//Digital Gamma

			29 01 00 00 00 00 02 00 80
			29 01 00 00 00 00 1D CA 80 20 40 50 60 70 80 90 a0 b0 c0 d0 e0 f0 f0 f0 AF FF AF FF 63 FF 05 03 05 03 05 03
			29 01 00 00 00 00 02 00 00
			29 01 00 00 00 00 02 C7 10
			29 01 00 00 00 00 13 C8 80 99 99 99 A9 AA 99 99 99 99 99 99 89 78 67 56 45 33
			29 01 00 00 00 00 02 00 00
			29 01 00 00 00 00 02 C7 11
			29 01 00 00 00 00 13 C8 80 99 99 99 A9 AA 99 99 99 99 99 99 89 78 67 56 45 33
			29 01 00 00 00 00 02 00 00
			29 01 00 00 00 00 02 C7 12
			29 01 00 00 00 00 13 C8 80 99 99 99 99 9A 99 99 99 99 99 99 88 88 77 66 45 33
			29 01 00 00 00 00 02 00 00
			29 01 00 00 00 00 02 C7 13
			29 01 00 00 00 00 13 C8 80 99 99 99 99 89 99 99 99 99 99 99 88 88 78 67 45 33
			29 01 00 00 00 00 02 00 00
			29 01 00 00 00 00 02 C7 14
			29 01 00 00 00 00 13 C8 80 99 99 99 99 88 99 99 99 99 99 89 88 88 88 77 45 33
			29 01 00 00 00 00 02 00 00
			29 01 00 00 00 00 02 C7 15
			29 01 00 00 00 00 13 C8 80 99 99 99 99 88 98 99 89 99 99 89 88 88 88 78 46 33
			29 01 00 00 00 00 02 00 00
			29 01 00 00 00 00 02 C7 16
			29 01 00 00 00 00 13 C8 80 99 99 99 89 88 98 99 89 98 99 89 88 88 88 78 56 34
			29 01 00 00 00 00 02 00 00
			29 01 00 00 00 00 02 C7 17
			29 01 00 00 00 00 13 C8 80 99 99 99 89 88 88 98 99 88 99 89 88 88 88 88 57 34
			29 01 00 00 00 00 02 00 00
			29 01 00 00 00 00 02 C7 18
			29 01 00 00 00 00 13 C8 80 99 99 99 89 88 88 88 98 99 99 88 88 88 88 77 67 45
			29 01 00 00 00 00 02 00 00
			29 01 00 00 00 00 02 C7 19
			29 01 00 00 00 00 13 C8 80 99 99 99 89 88 88 88 88 98 99 88 88 88 88 88 67 45
			29 01 00 00 00 00 02 00 00
			29 01 00 00 00 00 02 C7 1A
			29 01 00 00 00 00 13 C8 80 89 89 99 88 88 88 88 88 88 99 88 88 88 88 88 77 55
			29 01 00 00 00 00 02 00 00
			29 01 00 00 00 00 02 C7 1B
			29 01 00 00 00 00 13 C8 80 89 89 89 88 88 88 88 88 98 88 88 88 88 88 88 77 57
			29 01 00 00 00 00 02 00 00
			29 01 00 00 00 00 02 C7 1C
			29 01 00 00 00 00 13 C8 80 89 89 88 88 88 88 88 88 98 88 88 88 88 88 88 88 56
			29 01 00 00 00 00 02 00 00
			29 01 00 00 00 00 02 C7 1d
			29 01 00 00 00 00 13 C8 80 88 88 88 88 88 88 88 88 88 88 88 88 88 88 88 88 88
			29 01 00 00 00 00 02 00 00
			29 01 00 00 00 00 02 C7 00
			//CABC UI(min.) = 70%, ST & MV = 40%


			//OTM8018B initial code ...
			39 01 00 00 00 00 02 00 A0
			29 01 00 00 00 00 02 C1 EA  //for MIPI[0x02 for RGB]
			39 01 00 00 00 00 02 00 A6
			29 01 00 00 00 00 04 C1 01 00 00  //display on pump
			39 01 00 00 00 00 02 00 C6
			29 01 00 00 00 00 02 B0 03  //MIPI read
			39 01 00 00 00 00 02 00 80
			29 01 00 00 00 00 02 C4 30  //source sleep in pull low
			39 01 00 00 00 00 02 00 8A
			29 01 00 00 00 00 02 C4 40  //source sleep in pull low
			39 01 00 00 00 00 02 00 8B
			29 01 00 00 00 00 02 B0 40  //ULPM mode
			39 01 00 00 00 00 02 00 B6
			29 01 00 00 00 00 02 F5 06  //VGL & VGL_REG short
			39 01 00 00 00 00 02 00 B1
			29 01 00 00 00 00 02 B0 80  //MIPI HS rc delay
			39 01 00 00 00 00 02 00 80
			29 01 00 00 00 00 02 B3 80  //error report off
			39 01 00 00 00 00 02 00 92
			29 01 00 00 00 00 08 F5 0E 14 0E 14 00 14 00  //power on setp.
			39 01 00 00 00 00 02 00 81
			39 01 00 00 00 00 02 C1 66  //Frame rate set.
			39 01 00 00 00 00 02 00 B2
			29 01 00 00 00 00 05 F5 15 00 15 00  //VRGH disable
			39 01 00 00 00 00 02 00 93
			39 01 00 00 00 00 02 C5 03  //VRGH min.
			39 01 00 00 00 00 02 00 C0
			39 01 00 00 00 00 02 C5 00  //sleep in set.
			29 01 00 00 00 00 02 00 80
			39 01 00 00 00 00 02 C5 0B  //sleep out set
			39 01 00 00 00 00 02 00 B1
			39 01 00 00 00 00 02 C6 0A  //PWM 20KHz

			39 01 00 00 00 00 02 00 80 //CE function
			29 01 00 00 00 00 02 d6 98 //08 ~ F8: CE ON, 00: CE OFF


			39 01 00 00 00 00 02 00 80
			29 01 00 00 00 00 03 ff ff ff

			39 01 00 00 00 00 02 00 00
			29 01 00 00 00 00 04 ff ff ff ff

			//39 01 00 00 00 00 02 00 00
			//29 01 00 00 00 00 02 51 ff

			39 01 00 00 00 00 02 00 00
			29 01 00 00 00 00 02 53 2c

			39 01 00 00 00 00 02 00 00
			29 01 00 00 00 00 02 55 01 //00: OFF, 01: UI, 02: ST, 03:MV

			05 01 00 00 00 00 02 20 00
			05 01 00 00 78 00 02 11 00
			//05 01 00 00 0a 00 02 29 00
];
		qcom,mdss-dsi-off-command = [05 01 00 00 01 00 02 28 00
					05 01 00 00 82 00 02 10 00];
		qcom,mdss-dsi-on-command-state = "dsi_lp_mode";
		qcom,mdss-dsi-off-command-state = "dsi_hs_mode";
		qcom,mdss-dsi-h-sync-pulse = <1>;
		qcom,mdss-dsi-traffic-mode = <1>;
		qcom,mdss-dsi-bllp-eof-power-mode;
		qcom,mdss-dsi-lane-map = <0>;
		qcom,mdss-dsi-bllp-power-mode;
		qcom,mdss-dsi-lane-0-state;
		qcom,mdss-dsi-lane-1-state;
		qcom,mdss-dsi-panel-timings =  [c9 23 1b 00 36 31 20 25 2c 03 04 00];
		qcom,mdss-dsi-t-clk-post = <0x1f>;
		qcom,mdss-dsi-t-clk-pre = <0x39>;
		qcom,mdss-dsi-bl-min-level = <1>;
		qcom,mdss-dsi-bl-max-level = <255>;
		qcom,mdss-dsi-dma-trigger = <0x04>;
		qcom,mdss-dsi-mdp-trigger = <0x0>;
		qcom,mdss-dsi-bl-pmic-control-type = "bl_ctrl_dcs";

		qcom,display-on-cmds = [05 01 00 00 32 00 02 29 00];
		qcom,mdss-dsi-default-command-state = "dsi_hs_mode";
		qcom,mdss-pan-physical-width-dimension = <58>;
		qcom,mdss-pan-physical-height-dimension = <103>;
		qcom,mdss-shrink-pwm = <8 113 255>;
		qcom,mdss-shrink-pwm-power-hack = <16 73 255>;
		qcom,mdss-dsi-panel-framerate-power-hack = <56>;
		qcom,cont-splash-power-hack = <0>;
		qcom,mdss-dsi-lp11-init;
		htc,mdss-camera-blk = <213>;
		htc,panel-id=<0>;
		htc,cabc-off-cmds = [39 01 00 00 01 00 02 55 00];
		htc,cabc-ui-cmds = [39 01 00 00 01 00 02 55 02];
		htc,cabc-video-cmds = [39 01 00 00 01 00 02 55 03];
		htc,dimming-on-cmds = [39 01 00 00 00 00 02 53 2C];
		htc,mdss-pp-hue = <0xfef>;
	};

	qcom,mdss_dsi_auo_nt_qhd_video{
		compatible = "qcom,mdss-dsi-panel";
		status = "disabled";
		qcom,cont-splash-enabled;
		qcom,mdss-dsi-panel-name = "AUO nt qHD video mode dsi panel";
		qcom,mdss-dsi-panel-controller = <&mdss_dsi0>;
		qcom,mdss-dsi-panel-type = "dsi_video_mode";

		qcom,mdss-dsi-panel-destination = "display_1";
		qcom,mdss-dsi-panel-framerate = <60>;
		qcom,mdss-dsi-virtual-channel-id = <0>;
		qcom,mdss-dsi-stream = <0>;
		qcom,mdss-dsi-panel-width = <540>;
		qcom,mdss-dsi-panel-height = <960>;
		qcom,mdss-dsi-h-front-porch = <20>;
		qcom,mdss-dsi-h-back-porch = <60>;
		qcom,mdss-dsi-h-pulse-width = <2>;
		qcom,mdss-dsi-h-sync-skew = <0>;
		qcom,mdss-dsi-v-back-porch = <20>;
		qcom,mdss-dsi-v-front-porch = <20>;
		qcom,mdss-dsi-v-pulse-width = <2>;
		qcom,mdss-dsi-h-left-border = <0>;
		qcom,mdss-dsi-h-right-border = <0>;
		qcom,mdss-dsi-v-top-border = <0>;
		qcom,mdss-dsi-v-bottom-border = <0>;
		qcom,mdss-dsi-bpp = <24>;
		qcom,mdss-dsi-color-order = <0>;
		qcom,mdss-dsi-underflow-color = <0xff>;
		qcom,mdss-dsi-border-color = <0>;
		qcom,mdss-dsi-on-command = [
			39 01 00 00 01 00 05 FF AA 55 25 01
			15 01 00 00 01 00 02 6f 17
			15 01 00 00 01 00 02 f2 20
			15 01 00 00 01 00 02 6f 07
			15 01 00 00 01 00 02 f3 80
			39 01 00 00 01 00 06 f0 55 aa 52 08 00
			15 01 00 00 01 00 02 b3 82
			15 01 00 00 01 00 02 b6 05
			39 01 00 00 01 00 03 b7 11 11
			39 01 00 00 01 00 13 C8 01 00 5F 8A 5F 8A 5F 8A 5F 8A 8C 8C 8C 8C 8C 8C 8C 8C
			15 01 00 00 01 00 02 bc 02
			15 01 00 00 01 00 02 ba 06
			39 01 00 00 01 00 03 e0 00 02
			39 01 00 00 01 00 0b E3 FF FE FB F8 F3 ED E6 DE D7 D0

			15 01 00 00 01 00 02 53 2C
			15 01 00 00 01 00 02 55 92

			39 01 00 00 01 00 0A D4 00 00 00 00 00 00 00 00 00
			39 01 00 00 01 00 11 D6 00 05 10 17 22 26 29 29 26 23 17 12 06 02 01 00
			39 01 00 00 01 00 0D D7 30 30 30 28 00 00 00 00 00 00 00 00
			39 01 00 00 01 00 0E D8 00 00 00 00 00 00 00 00 00 00 28 30 00

			39 01 00 00 01 00 05 ff aa 55 25 01
			15 01 00 00 01 00 02 6f 09
			39 01 00 00 01 00 04 f5 14 16 16

			39 01 00 00 01 00 06 f0 55 aa 52 08 01
			15 01 00 00 01 00 02 b0 05
			15 01 00 00 01 00 02 b6 34
			15 01 00 00 01 00 02 b1 05
			15 01 00 00 01 00 02 b7 34
			15 01 00 00 01 00 02 b2 01
			15 01 00 00 01 00 02 b8 15
			15 01 00 00 01 00 02 b3 14
			15 01 00 00 01 00 02 b9 34
			15 01 00 00 01 00 02 b4 00
			15 01 00 00 01 00 02 ba 25
			39 01 00 00 01 00 04 bc 00 78 00
			39 01 00 00 01 00 04 bd 00 78 00
			39 01 00 00 01 00 11 D1 00 ea 00 ee 00 fd 01 09 01 14 01 29 01 3c 01 5D
			39 01 00 00 01 00 11 D2 01 7a 01 aa 01 D2 02 15 02 4c 02 4d 02 81 02 b9
			39 01 00 00 01 00 11 D3 02 dc 03 0c 03 29 03 4f 03 65 03 77 03 85 03 8e
			39 01 00 00 01 00 05 D4 03 8f 03 C1
			39 01 00 00 01 00 11 D5 00 ea 00 f0 00 fc 01 08 01 13 01 27 01 39 01 5a
			39 01 00 00 01 00 11 D6 01 78 01 a7 01 D0 02 14 02 4b 02 4c 02 81 02 b9
			39 01 00 00 01 00 11 D7 02 dd 03 0d 03 2b 03 51 03 68 03 78 03 82 03 88
			39 01 00 00 01 00 05 D8 03 8d 03 C1
			39 01 00 00 01 00 11 D9 00 22 00 33 00 57 00 73 00 8c 00 b4 00 d5 01 0b
			39 01 00 00 01 00 11 DD 01 36 01 7a 01 ad 01 fe 02 3d 02 3f 02 73 02 b0
			39 01 00 00 01 00 11 DE 02 d4 03 03 03 20 03 45 03 5b 03 63 03 70 03 72
			39 01 00 00 01 00 05 DF 03 73 03 C1
			39 01 00 00 01 00 11 e0 00 ea 00 ee 00 fd 01 09 01 14 01 29 01 3c 01 5D
			39 01 00 00 01 00 11 e1 01 7a 01 aa 01 D2 02 15 02 4c 02 4d 02 81 02 b9
			39 01 00 00 01 00 11 e2 02 dc 03 0c 03 29 03 4f 03 65 03 77 03 85 03 8e
			39 01 00 00 01 00 05 e3 03 8f 03 C1
			39 01 00 00 01 00 11 e4 00 ea 00 f0 00 fc 01 08 01 13 01 27 01 39 01 5a
			39 01 00 00 01 00 11 e5 01 78 01 a7 01 D0 02 14 02 4b 02 4c 02 81 02 b9
			39 01 00 00 01 00 11 e6 02 dd 03 0d 03 2b 03 51 03 68 03 78 03 82 03 88
			39 01 00 00 01 00 05 e7 03 8d 03 C1
			39 01 00 00 01 00 11 e8 00 22 00 33 00 57 00 73 00 8c 00 b4 00 d5 01 0b
			39 01 00 00 01 00 11 e9 01 36 01 7a 01 ad 01 fe 02 3d 02 3f 02 73 02 b0
			39 01 00 00 01 00 11 ea 02 d4 03 03 03 20 03 45 03 5b 03 63 03 70 03 72
			39 01 00 00 01 00 05 eb 03 73 03 C1
			15 01 00 00 01 00 02 35 00
			15 01 00 00 01 00 02 53 2C
			05 01 00 00 C8 00 02 11 00
			39 01 00 00 01 00 06 f0 55 aa 52 08 01
			15 01 00 00 11 00 02 b4 06];
		qcom,mdss-dsi-off-command = [05 01 00 00 01 00 02 28 00
					05 01 00 00 82 00 02 10 00];
		qcom,mdss-dsi-on-command-state = "dsi_lp_mode";
		qcom,mdss-dsi-off-command-state = "dsi_hs_mode";

		htc,cabc-off-cmds = [39 01 00 00 01 00 02 55 00];
		htc,cabc-ui-cmds = [
			39 01 00 00 01 00 0b E3 FF FE FB F8 F3 ED E6 DE D7 D0
			39 01 00 00 05 00 02 55 92
			39 01 00 00 01 00 05 ff aa 55 25 01
			15 01 00 00 01 00 02 6f 09
			39 01 00 00 01 00 04 f5 14 16 16
		];
		htc,cabc-video-cmds = [
			39 01 00 00 01 00 0b E3 FF FB F9 F7 F3 E2 DA AD 90 76
			39 01 00 00 05 00 02 55 92
			39 01 00 00 01 00 05 ff aa 55 25 01
			15 01 00 00 01 00 02 6f 09
			39 01 00 00 01 00 04 f5 1A 1C 1F
		];
		htc,dimming-on-cmds = [39 01 00 00 00 00 02 53 2C];

		qcom,mdss-dsi-h-sync-pulse = <1>;
		qcom,mdss-dsi-traffic-mode = <1>;
		qcom,mdss-dsi-bllp-eof-power-mode;
		qcom,mdss-dsi-lane-map = <0>;
		qcom,mdss-dsi-bllp-power-mode;
		qcom,mdss-dsi-lane-0-state;
		qcom,mdss-dsi-lane-1-state;
		qcom,mdss-dsi-panel-timings =  [37 27 20 01 3c 39 21
					29 32 03 04 00];
		qcom,mdss-dsi-t-clk-post = <0x1f>;
		qcom,mdss-dsi-t-clk-pre = <0x39>;
		qcom,mdss-dsi-bl-min-level = <1>;
		qcom,mdss-dsi-bl-max-level = <255>;
		qcom,mdss-dsi-dma-trigger = <0x04>;
		qcom,mdss-dsi-mdp-trigger = <0x0>;
		qcom,mdss-dsi-bl-pmic-control-type = "bl_ctrl_dcs";

		qcom,display-on-cmds = [05 01 00 00 28 00 02 29 00];
		qcom,mdss-dsi-default-command-state = "dsi_hs_mode";
		qcom,mdss-pan-physical-width-dimension = <58>;
		qcom,mdss-pan-physical-height-dimension = <103>;
		qcom,mdss-shrink-pwm = <16 113 255>;
		qcom,mdss-dsi-lp11-init;
		htc,mdss-camera-blk = <213>;
		htc,panel-id=<0>;
	};
};
